# bcm2837_lpa register map
Vendor: BROADCOM; Series: BCM2837; File version: A
CPU: CA72 r0p0, little endian, MPU, FPU, 2 interrupt priority bits
Registers are 32-bit, read-write, reset 0x0 unless marked. A register's access mark holds for its fields unless they carry their own. Offsets are from the block's base; [hi:lo] are bit positions; 'fields as' and 'values as' point back to an identical list.

## USB_OTG_PWRCLK — USB on the go high speed power control
Base 0x3F980E00
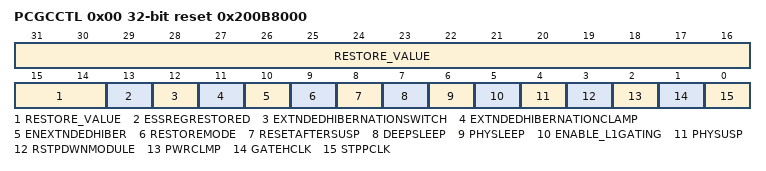
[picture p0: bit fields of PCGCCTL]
0x00 PCGCCTL reset 0x200B8000 — power and clock gating control
  [31:14] RESTORE_VALUE
  [13] ESSREGRESTORED — Essential register values restored
  [12] EXTNDEDHIBERNATIONSWITCH — Extended hibernation switch
  [11] EXTNDEDHIBERNATIONCLAMP — Extended hibernation clamp
  [10] ENEXTNDEDHIBER — Enable extended hibernation
  [9] RESTOREMODE
  [8] RESETAFTERSUSP — Reset after suspend
  [7] DEEPSLEEP — PHY is in deep sleep
  [6] PHYSLEEP — PHY is in sleep mode
  [5] ENABLE_L1GATING — Enable sleep clock gating
  [4] PHYSUSP — PHY Suspended
  [3] RSTPDWNMODULE — Power down modules
  [2] PWRCLMP — Power clamp
  [1] GATEHCLK
  [0] STPPCLK — Stop PHY clock

## PCM
Base 0x3F203000
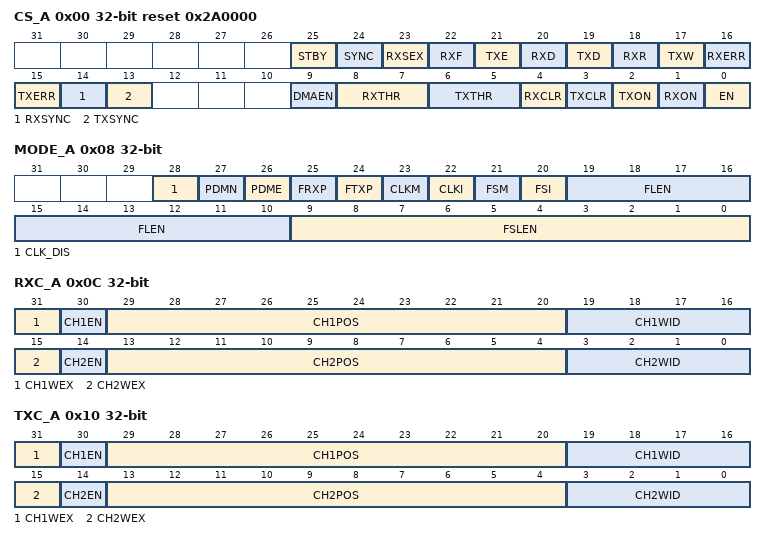
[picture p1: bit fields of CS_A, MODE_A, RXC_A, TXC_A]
0x00 CS_A access per field reset 0x2A0000 — PCM Control and Status
  [25] STBY rw — RAM Standby
  [24] SYNC rw — PCM Clock sync helper
  [23] RXSEX rw — RX Sign Extend
  [22] RXF ro — RX FIFO is Full
  [21] TXE ro — TX FIFO is Empty
  [20] RXD ro — Indicates that the RX FIFO contains data
  [19] TXD ro — Indicates that the TX FIFO can accept data
  [18] RXR ro — Indicates that the RX FIFO needs Reading
  [17] TXW ro — Indicates that the TX FIFO needs Writing
  [16] RXERR rw write-1-clears — RX FIFO Error
  [15] TXERR rw write-1-clears — TX FIFO Error
  [14] RXSYNC ro — RX FIFO Sync
  [13] TXSYNC ro — TX FIFO Sync
  [9] DMAEN rw — DMA DREQ Enable
  [8:7] RXTHR rw — Sets the RX FIFO threshold at which point the RXR flag is set
  [6:5] TXTHR rw — Sets the TX FIFO threshold at which point the TXW flag is set
  [4] RXCLR wo write-1-clears — Clear the RX FIFO
  [3] TXCLR wo write-1-clears — Clear the TX FIFO
  [2] TXON rw — Enable transmission
  [1] RXON rw — Enable reception
  [0] EN rw — Enable the PCM Audio Interface
0x04 FIFO_A — This is the FIFO port of the PCM
  [31:0] FIFO
0x08 MODE_A — This register defines the basic PCM Operating Mode
  [28] CLK_DIS — PCM Clock Disable
  [27] PDMN — PDM Decimation Factor (N)
  [26] PDME — PDM Input Mode Enable
  [25] FRXP — Receive Frame Packed Mode
  [24] FTXP — Transmit Frame Packed Mode
  [23] CLKM — PCM Clock Mode
  [22] CLKI — Clock Invert this logically inverts the PCM_CLK signal
  [21] FSM — Frame Sync Mode
  [20] FSI — Frame Sync Invert This logically inverts the frame sync signal
  [19:10] FLEN — Frame Length
  [9:0] FSLEN — Frame Sync Length
0x0C RXC_A — Sets the Channel configurations for Receiving
  [31] CH1WEX — Channel 1 Width Extension Bit
  [30] CH1EN — Channel 1 Enable
  [29:20] CH1POS — Channel 1 Position
  [19:16] CH1WID — Channel 1 Width
  [15] CH2WEX — Channel 2 Width Extension Bit
  [14] CH2EN — Channel 2 Enable
  [13:4] CH2POS — Channel 2 Position
  [3:0] CH2WID — Channel 2 Width
0x10 TXC_A — Sets the Channel configurations for Transmitting
  fields as RXC_A
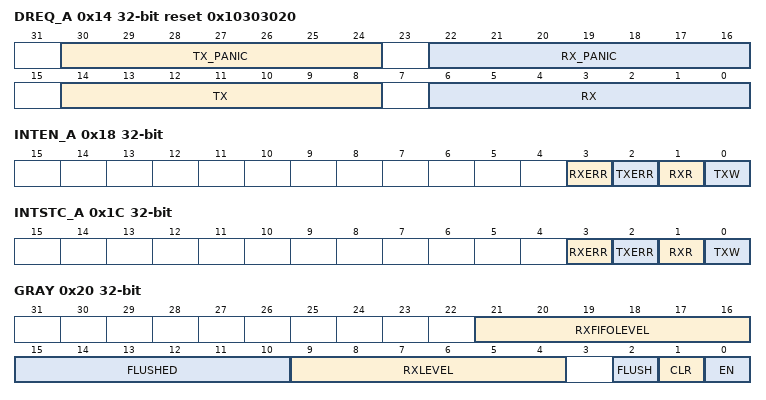
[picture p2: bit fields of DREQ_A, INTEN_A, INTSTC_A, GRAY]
0x14 DREQ_A reset 0x10303020 — Set the DMA DREQ and Panic thresholds
  [30:24] TX_PANIC — TX Panic Level
  [22:16] RX_PANIC — RX Panic Level
  [14:8] TX — TX Request Level
  [6:0] RX — RX Request Level
0x18 INTEN_A — Set the reasons for generating an Interrupt
  [3] RXERR — RX Error Interrupt
  [2] TXERR — TX Error Interrupt
  [1] RXR — RX Read Interrupt Enable
  [0] TXW — TX Write Interrupt Enable
0x1C INTSTC_A — This register is used to read and clear the PCM interrupt status
  [3] RXERR — RX Error Interrupt Status / Clear
  [2] TXERR — TX Error Interrupt Status / Clear
  [1] RXR — RX Read Interrupt Status / Clear
  [0] TXW — TX Write Interrupt Status / Clear
0x20 GRAY access per field — This register is used to control the gray mode generation
  [21:16] RXFIFOLEVEL ro — The Current level of the RXFIFO
  [15:10] FLUSHED ro — The Number of bits that were flushed into the RXFIFO
  [9:4] RXLEVEL ro — The Current fill level of the RX Buffer
  [2] FLUSH rw — Flush the RX Buffer into the RX FIFO
  [1] CLR rw — Clear the GRAY Mode Logic
  [0] EN rw — Enable GRAY Mode
